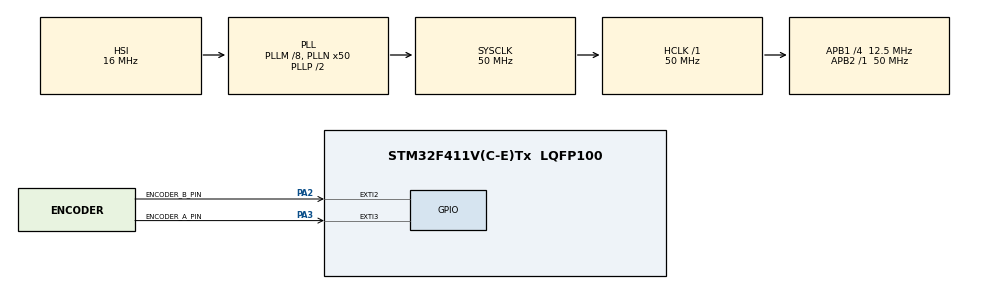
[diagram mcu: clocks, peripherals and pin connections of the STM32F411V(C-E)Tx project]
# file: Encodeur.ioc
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Mcu.Family=STM32F4
Mcu.Name=STM32F411V(C-E)Tx
Mcu.Package=LQFP100
NVIC.EXTI2_IRQn=true\:0\:0\:false\:false\:true\:true\:true\:true
NVIC.EXTI3_IRQn=true\:0\:0\:false\:false\:true\:true\:true\:true
NVIC.PriorityGroup=NVIC_PRIORITYGROUP_1
NVIC.TIM2_IRQn=true\:0\:0\:false\:false\:true\:true\:true\:true
PA2.GPIO_Label=ENCODER_B_PIN
PA2.GPIO_ModeDefaultEXTI=GPIO_MODE_IT_RISING_FALLING
PA2.Signal=GPXTI2
PA3.GPIO_Label=ENCODER_A_PIN
PA3.GPIO_ModeDefaultEXTI=GPIO_MODE_IT_RISING_FALLING
PA3.Signal=GPXTI3
ProjectManager.HeapSize=0x200
ProjectManager.StackSize=0x400
ProjectManager.TargetToolchain=STM32CubeIDE
RCC.48MHZClocksFreq_Value=12500000
RCC.AHBFreq_Value=50000000
RCC.APB1CLKDivider=RCC_HCLK_DIV4
RCC.APB1Freq_Value=12500000
RCC.APB1TimFreq_Value=25000000
RCC.APB2Freq_Value=50000000
RCC.APB2TimFreq_Value=50000000
RCC.CortexFreq_Value=50000000
RCC.HCLKFreq_Value=50000000
RCC.HSE_VALUE=8000000
RCC.HSI_VALUE=16000000
RCC.PLLI2SM=5
RCC.PLLI2SN=200
RCC.PLLM=8
RCC.PLLN=50
RCC.PLLQ=8
RCC.SYSCLKFreq_VALUE=50000000
RCC.SYSCLKSource=RCC_SYSCLKSOURCE_PLLCLK
RCC.VCOOutputFreq_Value=100000000
TIM2.Channel-Output\ Compare1\ No\ Output=TIM_CHANNEL_1
TIM2.ClockDivision=TIM_CLOCKDIVISION_DIV1
TIM2.Period=1000-1
VP_TIM2_VS_OPM.Mode=OPM_bit
VP_TIM2_VS_no_output1.Mode=Output Compare1 No Output
board=STM32F411E-DISCO

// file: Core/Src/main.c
/* USER CODE BEGIN Header */
/**
  ******************************************************************************
  * @file           : main.c
  * @brief          : Main program body
  ******************************************************************************
  * @attention
  *
  * Copyright (c) 2024 STMicroelectronics.
  * All rights reserved.
  *
  * This software is licensed under terms that can be found in the LICENSE file
  * in the root directory of this software component.
  * If no LICENSE file comes with this software, it is provided AS-IS.
  *
  ******************************************************************************
  */
/* USER CODE END Header */
#include "main.h"
#include "tim.h"
#include "gpio.h"
#include <stdio.h>
/* USER CODE BEGIN Includes */
/* Constants */
#define ENCODER_A_PIN GPIO_PIN_2 // Replace with Tach B pin
#define ENCODER_B_PIN GPIO_PIN_3 // Replace with Tach A pin
#define ENCODER_PPR 400        // Encoder pulses per revolution
#define GPIO_PORTA GPIOA

/* Variables */
extern volatile uint32_t encoder_count ;
extern volatile float speed ;
extern volatile float angle ;

/*volatile uint32_t encoder_count =1; // encoder pulses
#define SAMPLE_TIME_MS 10
float speed=0.0f ;
float angle=0.0f ;*/
char CH1[50],CH2[50]; // Assuming a maximum of 50 characters for the string
/* USER CODE END Includes */

void SystemClock_Config(void);

int main(void)
{

  /* MCU Configuration--------------------------------------------------------*/

  /* Reset of all peripherals, Initializes the Flash interface and the Systick. */
  HAL_Init();

  MX_GPIO_Init(); // Initialize GPIO pins
  MX_TIM2_Init(); // Initialize Timer 3 for encoder

  // Enable EXTI for encoder pins (if not already done in MX_GPIO_Init())
  HAL_GPIO_EXTI_Callback(0); // Clear any pending EXTI interrupts (optional)

  HAL_TIM_Base_Start_IT(&htim2);

  /* Configure the system clock */
  SystemClock_Config();

  /* Initialize all configured peripherals */
  HAL_TIM_Encoder_Start_IT(&htim2, TIM_CHANNEL_ALL); // Start encoder readings with interrupts

  /* Infinite loop */
  /* USER CODE BEGIN WHILE */
  while (1)
  {
	  sprintf(CH1, "Speed: %.2f RPM\n", speed);
	  printf("%s", CH1);

	  sprintf(CH2, "Angle: %.2f degrees\n", angle);
	  printf("%s", CH2);
	  HAL_Delay(1000);
    /* USER CODE END WHILE */

  }
}

void SystemClock_Config(void)
{
  RCC_OscInitTypeDef RCC_OscInitStruct = {0};
  RCC_ClkInitTypeDef RCC_ClkInitStruct = {0};

  /** Configure the main internal regulator output voltage
  */
  __HAL_RCC_PWR_CLK_ENABLE();
  __HAL_PWR_VOLTAGESCALING_CONFIG(PWR_REGULATOR_VOLTAGE_SCALE1);

  /** Initializes the RCC Oscillators according to the specified parameters
  * in the RCC_OscInitTypeDef structure.
  */
  RCC_OscInitStruct.OscillatorType = RCC_OSCILLATORTYPE_HSI;
  RCC_OscInitStruct.HSIState = RCC_HSI_ON;
  RCC_OscInitStruct.HSICalibrationValue = RCC_HSICALIBRATION_DEFAULT;
  RCC_OscInitStruct.PLL.PLLState = RCC_PLL_ON;
  RCC_OscInitStruct.PLL.PLLSource = RCC_PLLSOURCE_HSI;
  RCC_OscInitStruct.PLL.PLLM = 8;
  RCC_OscInitStruct.PLL.PLLN = 50;
  RCC_OscInitStruct.PLL.PLLP = RCC_PLLP_DIV2;
  RCC_OscInitStruct.PLL.PLLQ = 8;
  if (HAL_RCC_OscConfig(&RCC_OscInitStruct) != HAL_OK)
  {
    Error_Handler();
  }

  /** Initializes the CPU, AHB and APB buses clocks
  */
  RCC_ClkInitStruct.ClockType = RCC_CLOCKTYPE_HCLK|RCC_CLOCKTYPE_SYSCLK
                              |RCC_CLOCKTYPE_PCLK1|RCC_CLOCKTYPE_PCLK2;
  RCC_ClkInitStruct.SYSCLKSource = RCC_SYSCLKSOURCE_PLLCLK;
  RCC_ClkInitStruct.AHBCLKDivider = RCC_SYSCLK_DIV1;
  RCC_ClkInitStruct.APB1CLKDivider = RCC_HCLK_DIV4;
  RCC_ClkInitStruct.APB2CLKDivider = RCC_HCLK_DIV1;

  if (HAL_RCC_ClockConfig(&RCC_ClkInitStruct, FLASH_LATENCY_1) != HAL_OK)
  {
    Error_Handler();
  }
}

void Error_Handler(void)
{
  __disable_irq();
  while (1)
  {
  }
}
